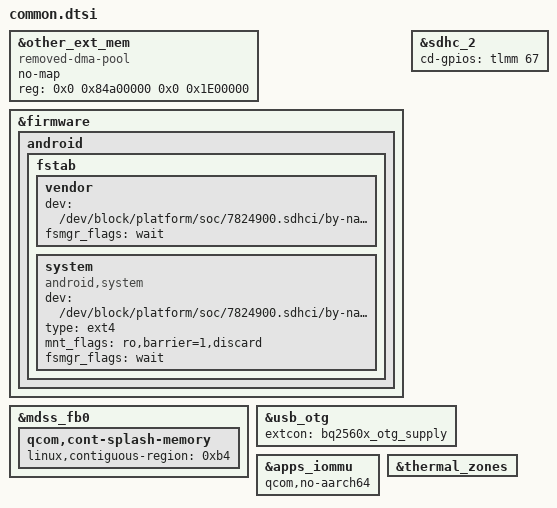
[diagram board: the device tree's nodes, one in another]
/*
 * Copyright (c) 2015-2016, The Linux Foundation. All rights reserved.
 * Copyright (C) 2018 XiaoMi, Inc.
 *
 * This program is free software; you can redistribute it and/or modify
 * it under the terms of the GNU General Public License version 2 and
 * only version 2 as published by the Free Software Foundation.
 *
 * This program is distributed in the hope that it will be useful,
 * but WITHOUT ANY WARRANTY; without even the implied warranty of
 * MERCHANTABILITY or FITNESS FOR A PARTICULAR PURPOSE.  See the
 * GNU General Public License for more details.
 */

#include "common-disable.dtsi"

#include "common-audio.dtsi"
#include "common-battery.dtsi"
#include "common-mdss.dtsi"
#include "common-misc.dtsi"
#include "common-mtp.dtsi"
#include "common-pinctrl.dtsi"
#include "common-pm.dtsi"
#include "common-touchscreen.dtsi"

&other_ext_mem {
	compatible = "removed-dma-pool";
	no-map;
	reg = <0x0 0x84a00000 0x0 0x1E00000>;
};

&firmware {
	android {
		/delete-node/ vbmeta;
		fstab {
			vendor {
				dev = "/dev/block/platform/soc/7824900.sdhci/by-name/cust";
				fsmgr_flags = "wait";
			};
			system {
				compatible = "android,system";
				dev = "/dev/block/platform/soc/7824900.sdhci/by-name/system";
				type = "ext4";
				mnt_flags = "ro,barrier=1,discard";
				fsmgr_flags = "wait";
				status = "ok";
			};
		};
	};
};

&sdhc_2 {
	cd-gpios = <&tlmm 67 0x0>;
};

&mdss_fb0 {
	qcom,cont-splash-memory {
		linux,contiguous-region = <0xb4>;
	};
};

&usb_otg {
	extcon = <&bq2560x_otg_supply>;
};

&apps_iommu {
	qcom,no-aarch64;
};

&thermal_zones {
    /delete-node/ pa-therm1-adc;
};
